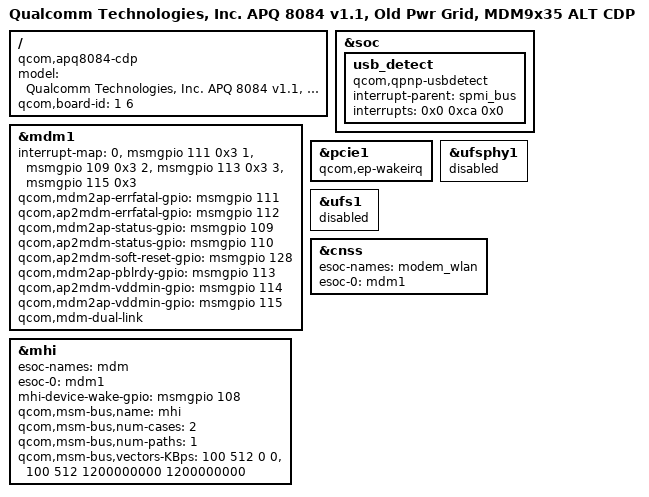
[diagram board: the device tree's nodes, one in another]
/* Copyright (c) 2014, The Linux Foundation. All rights reserved.
 *
 * This program is free software; you can redistribute it and/or modify
 * it under the terms of the GNU General Public License version 2 and
 * only version 2 as published by the Free Software Foundation.
 *
 * This program is distributed in the hope that it will be useful,
 * but WITHOUT ANY WARRANTY; without even the implied warranty of
 * MERCHANTABILITY or FITNESS FOR A PARTICULAR PURPOSE.  See the
 * GNU General Public License for more details.
 */

/dts-v1/;

#include "apq8084-v1.1.dtsi"
#include "apq8084-old-pwr-grid.dtsi"
#include "apq8084-cdp.dtsi"

/ {
	model = "Qualcomm Technologies, Inc. APQ 8084 v1.1, Old Pwr Grid, MDM9x35 ALT CDP";
	compatible = "qcom,apq8084-cdp", "qcom,apq8084", "qcom,cdp";
	qcom,board-id = <1 6>;
};

&soc {
	/* No smb charger */
	usb_detect {
		compatible = "qcom,qpnp-usbdetect";
		interrupt-parent = <&spmi_bus>;
		interrupts = <0x0 0xca 0x0>;  /* PMA8084 GPIO 11 */
		interrupt-names = "vbus_det_irq";
	};
};

&mdm1 {
	interrupt-map = <0 &msmgpio 111 0x3
			1 &msmgpio 109 0x3
			2 &msmgpio 113 0x3
			3 &msmgpio 115 0x3>;
	qcom,mdm2ap-errfatal-gpio = <&msmgpio 111 0x00>;
	qcom,ap2mdm-errfatal-gpio = <&msmgpio 112 0x00>;
	qcom,mdm2ap-status-gpio   = <&msmgpio 109 0x00>;
	qcom,ap2mdm-status-gpio   = <&msmgpio 110 0x00>;
	qcom,ap2mdm-soft-reset-gpio = <&msmgpio 128 0x00>;
	qcom,mdm2ap-pblrdy-gpio = <&msmgpio 113 0x00>;
	qcom,ap2mdm-vddmin-gpio = <&msmgpio 114 0x00>;
	qcom,mdm2ap-vddmin-gpio = <&msmgpio 115 0x00>;
	qcom,mdm-dual-link;
	status = "ok";
};

&pcie1 {
	qcom,ep-wakeirq;
};

&mhi {
	esoc-names = "mdm";
	esoc-0 = <&mdm1>;
	mhi-device-wake-gpio =
		<&msmgpio 108 0>;
	qcom,msm-bus,name = "mhi";
	qcom,msm-bus,num-cases = <2>;
	qcom,msm-bus,num-paths = <1>;
	qcom,msm-bus,vectors-KBps =
			<100 512 0 0>,
			<100 512 1200000000 1200000000>;
};
&ufsphy1 {
	status = "disabled";
};

&ufs1 {
	status = "disabled";
};

&cnss {
	esoc-names = "modem_wlan";
	esoc-0 = <&mdm1>;
};
